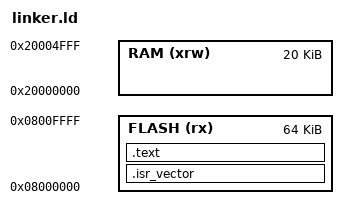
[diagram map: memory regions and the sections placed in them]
MEMORY
{
    FLASH (rx) : ORIGIN = 0x08000000, LENGTH = 64K
    RAM (xrw)  : ORIGIN = 0x20000000, LENGTH = 20K
}

_stack_top = ORIGIN(RAM) + LENGTH(RAM);

SECTIONS
{
    .isr_vector :
    {
        KEEP(*(.isr_vector))
        KEEP(*(.reset_handler))
    } > FLASH

    .text :
    {
        *(.text*)
        *(.rodata*)
    } > FLASH
}
